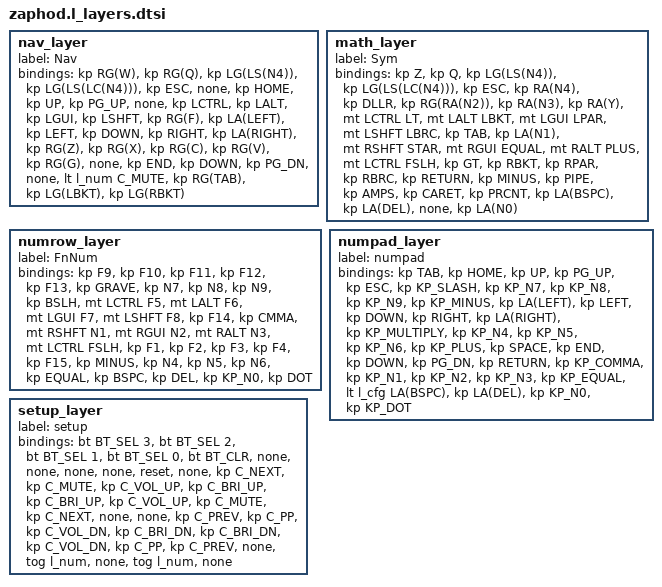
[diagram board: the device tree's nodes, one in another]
/*
 Building for a 34 key board
 */

//                                     shorcuts & Navigation
//╭────────────────────────────────────────────╮ ╭──────────────────────────────────────────╮
//|  close |   quit  | ScrCp | SelCp |   ESC   | |       |  HOME  |   UP   |  PG_UP |       |
//|   ctrl |   alt   |  gui  |  shft |   Find  | | Lword |  LEFT  |  DOWN  |   RGT  | Rword |
//|  undo  |   cut   |  copy |  pste | findAgn | |       |   END  |        |  PG_DN |       |
//╰──────────────────╮       | dwdlt |  dwdrt  | |  back |  fwd   |        ╭────────────────╯
//                   ╰─────────────────────────╯ ╰─────────────────────────╯
                nav_layer {
                    label = "Nav";
                    bindings = <
&kp RG(W) &kp RG(Q) &kp LG(LS(N4)) &kp LG(LS(LC(N4))) &kp ESC  &none        &kp HOME &kp UP    &kp PG_UP &none
&kp LCTRL  &kp LALT &kp LGUI &kp LSHFT   &kp RG(F)               &kp LA(LEFT) &kp LEFT &kp DOWN  &kp RIGHT &kp LA(RIGHT)
&kp RG(Z)  &kp RG(X) &kp RG(C) &kp RG(V) &kp RG(G)               &none        &kp END  &kp DOWN  &kp PG_DN &none
                     &lt l_num C_MUTE     &kp RG(TAB)        &kp LG(LBKT) &kp LG(RBKT)
                    >;
                };

//                                       Symbol & math
//╭────────────────────────────────────────────╮ ╭──────────────────────────────────────────╮
//|    Z   |    Q    | ScrCp | SelCp |   ESC   | |   ¢   |    $   |    €   |    £   |   ¥   |
//|    <   |    [    |   (   |   {   |   TAB   | |   ¡   |    *   |    =   |    +   |   /   |
//|    >   |    ]    |   )   |   }   |   RET   | |   _   |    |   |    &   |    ^   |   %   |
//╰──────────────────╮       |  BKSP |   DEL   | |       |    °   |        ╭────────────────╯
//                   ╰─────────────────────────╯ ╰─────────────────────────╯
                math_layer {
                    label = "Sym";
                    bindings = <
&kp Z &kp Q &kp LG(LS(N4)) &kp LG(LS(LC(N4))) &kp ESC             &kp RA(N4) &kp DLLR  &kp RG(RA(N2)) &kp RA(N3) &kp RA(Y)
&mt LCTRL LT  &mt LALT LBKT &mt LGUI LPAR &mt LSHFT LBRC &kp TAB  &kp LA(N1) &mt RSHFT STAR  &mt RGUI EQUAL &mt RALT PLUS  &mt LCTRL FSLH
&kp GT  &kp RBKT &kp RPAR &kp RBRC &kp RETURN                     &kp MINUS  &kp PIPE  &kp AMPS     &kp CARET &kp PRCNT
                &kp LA(BSPC)   &kp LA(DEL)              &none      &kp LA(N0)
                    >;
                };

//                                         Fkey & Num Row (optimized)
//╭────────────────────────────────────────────╮ ╭───────────────────────────────────────╮
//|    F9   |  F10   |  F11   |  F12   |  F13  | |   `   |   7   |   8   |   9   |   \   |
//|   C/F5  |  A/F6  |  G/F7  |  S/F8  |  F14  | |   ,   |  S/1  |  G/2  |  A/3  |  C//  |
//|    F1   |   F2   |   F3   |   F4   |  F15  | |   -   |   4   |   5   |   6   |   =   |
//╰──────────────────╮        |  dwdlt | dwdrt | |   0   |   .   |       ╭───────────────╯
//                   ╰─────────────────────────╯ ╰───────────────────────╯

                numrow_layer {
                        label = "FnNum";
                        bindings = <

&kp F9       &kp F10     &kp F11      &kp F12      &kp F13 &kp GRAVE &kp N7       &kp N8      &kp N9      &kp BSLH
&mt LCTRL F5 &mt LALT F6 &mt LGUI F7  &mt LSHFT F8 &kp F14 &kp CMMA  &mt RSHFT N1 &mt RGUI N2 &mt RALT N3 &mt LCTRL FSLH
&kp F1       &kp F2      &kp F3       &kp F4       &kp F15 &kp MINUS &kp N4       &kp N5      &kp N6      &kp EQUAL
                    &kp BSPC     &kp DEL          &kp KP_N0    &kp DOT
                        >;
                };


//                                          Nav & NumPad (standard)
//╭────────────────────────────────────────────╮ ╭────────────────────────────────────────╮
//|   TAB  |  HOME  |   UP   |  PG_UP |  ESC   | |    /   |   7   |   8   |   9   |   -   |
//|  Lword |  LEFT  |  DOWN  |   RGT  | Rword  | |    *   |   4   |   5   |   6   |   +   |
//|   SPC  |   END  |  DOWN  |  PG_DN |  RET   | |    ,   |   1   |   2   |   3   |   =   |
//╰─────────────────╮        |  dwlft | dwdrt  | |    0   |   .   |       ╭───────────────╯
//                  ╰──────────────────────────╯ ╰────────────────────────╯
                numpad_layer {
                        label = "numpad";
                        bindings = <

&kp TAB      &kp HOME &kp UP   &kp PG_UP  &kp ESC       &kp KP_SLASH    &kp KP_N7 &kp KP_N8 &kp KP_N9 &kp KP_MINUS
&kp LA(LEFT) &kp LEFT &kp DOWN &kp RIGHT  &kp LA(RIGHT) &kp KP_MULTIPLY &kp KP_N4 &kp KP_N5 &kp KP_N6 &kp KP_PLUS
&kp SPACE    &kp END  &kp DOWN &kp PG_DN  &kp RETURN    &kp KP_COMMA    &kp KP_N1 &kp KP_N2 &kp KP_N3 &kp KP_EQUAL
                       &lt l_cfg LA(BSPC) &kp LA(DEL)   &kp KP_N0  &kp KP_DOT
                        >;
                };

//                                     Keyboard & System Settings
                setup_layer {
                        label = "setup";
                        bindings = <
//&none &none &none &none &none &none &none &none &none &none &none &none
&bt BT_SEL 3 &bt BT_SEL 2 &bt BT_SEL 1 &bt BT_SEL 0 &bt BT_CLR   &none &none        &none      &none        &reset
&none        &kp C_NEXT   &kp C_MUTE   &kp C_VOL_UP &kp C_BRI_UP &kp C_BRI_UP &kp C_VOL_UP &kp C_MUTE &kp C_NEXT &none
&none        &kp C_PREV   &kp C_PP     &kp C_VOL_DN &kp C_BRI_DN &kp C_BRI_DN &kp C_VOL_DN &kp C_PP   &kp C_PREV   &none
                                        &tog l_num   &none        &tog l_num   &none
                        >;
                };
